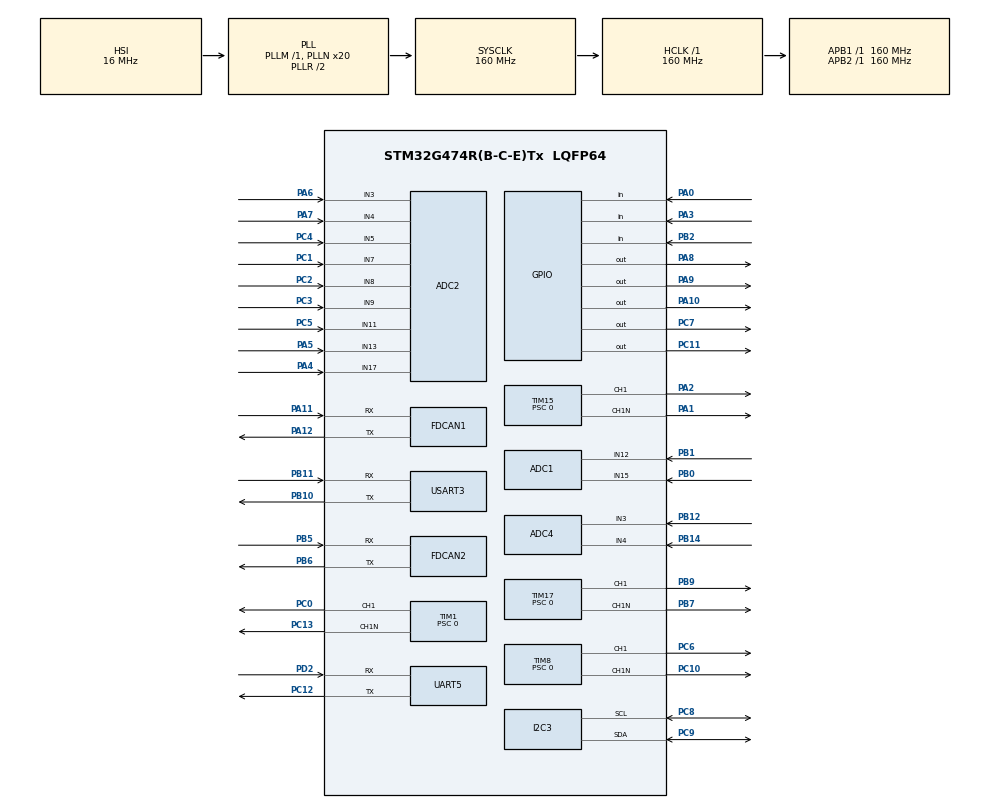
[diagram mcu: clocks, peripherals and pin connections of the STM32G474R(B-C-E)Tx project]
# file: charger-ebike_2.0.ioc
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ADC1.Channel-3\#ChannelRegularConversion=ADC_CHANNEL_15
ADC1.Channel-4\#ChannelRegularConversion=ADC_CHANNEL_12
ADC1.ContinuousConvMode=ENABLE
ADC1.DMAContinuousRequests=ENABLE
ADC1.NbrOfConversion=2
ADC1.NbrOfConversionFlag=1
ADC1.OffsetNumber-3\#ChannelRegularConversion=ADC_OFFSET_NONE
ADC1.OffsetNumber-4\#ChannelRegularConversion=ADC_OFFSET_NONE
ADC1.Rank-3\#ChannelRegularConversion=1
ADC1.Rank-4\#ChannelRegularConversion=2
ADC1.SamplingTime-3\#ChannelRegularConversion=ADC_SAMPLETIME_640CYCLES_5
ADC1.SamplingTime-4\#ChannelRegularConversion=ADC_SAMPLETIME_640CYCLES_5
ADC1.master=1
ADC2.Channel-0\#ChannelRegularConversion=ADC_CHANNEL_7
ADC2.Channel-1\#ChannelRegularConversion=ADC_CHANNEL_8
ADC2.Channel-2\#ChannelRegularConversion=ADC_CHANNEL_9
ADC2.Channel-3\#ChannelRegularConversion=ADC_CHANNEL_17
ADC2.Channel-4\#ChannelRegularConversion=ADC_CHANNEL_13
ADC2.Channel-5\#ChannelRegularConversion=ADC_CHANNEL_3
ADC2.Channel-6\#ChannelRegularConversion=ADC_CHANNEL_4
ADC2.Channel-7\#ChannelRegularConversion=ADC_CHANNEL_5
ADC2.Channel-8\#ChannelRegularConversion=ADC_CHANNEL_11
ADC2.ContinuousConvMode=ENABLE
ADC2.DMAContinuousRequests=ENABLE
ADC2.NbrOfConversion=9
ADC2.NbrOfConversionFlag=1
ADC2.OffsetNumber-0\#ChannelRegularConversion=ADC_OFFSET_NONE
ADC2.OffsetNumber-1\#ChannelRegularConversion=ADC_OFFSET_NONE
ADC2.OffsetNumber-2\#ChannelRegularConversion=ADC_OFFSET_NONE
ADC2.OffsetNumber-3\#ChannelRegularConversion=ADC_OFFSET_NONE
ADC2.OffsetNumber-4\#ChannelRegularConversion=ADC_OFFSET_NONE
ADC2.OffsetNumber-5\#ChannelRegularConversion=ADC_OFFSET_NONE
ADC2.OffsetNumber-6\#ChannelRegularConversion=ADC_OFFSET_NONE
ADC2.OffsetNumber-7\#ChannelRegularConversion=ADC_OFFSET_NONE
ADC2.OffsetNumber-8\#ChannelRegularConversion=ADC_OFFSET_NONE
ADC2.OversamplingMode=ENABLE
ADC2.Rank-0\#ChannelRegularConversion=1
ADC2.Rank-1\#ChannelRegularConversion=2
ADC2.Rank-2\#ChannelRegularConversion=3
ADC2.Rank-3\#ChannelRegularConversion=4
ADC2.Rank-4\#ChannelRegularConversion=5
ADC2.Rank-5\#ChannelRegularConversion=6
ADC2.Rank-6\#ChannelRegularConversion=7
ADC2.Rank-7\#ChannelRegularConversion=8
ADC2.Rank-8\#ChannelRegularConversion=9
ADC2.Ratio=ADC_OVERSAMPLING_RATIO_16
ADC2.RightBitShift=ADC_RIGHTBITSHIFT_4
ADC2.SamplingTime-0\#ChannelRegularConversion=ADC_SAMPLETIME_640CYCLES_5
ADC2.SamplingTime-1\#ChannelRegularConversion=ADC_SAMPLETIME_640CYCLES_5
ADC2.SamplingTime-2\#ChannelRegularConversion=ADC_SAMPLETIME_640CYCLES_5
ADC2.SamplingTime-3\#ChannelRegularConversion=ADC_SAMPLETIME_640CYCLES_5
ADC2.SamplingTime-4\#ChannelRegularConversion=ADC_SAMPLETIME_640CYCLES_5
ADC2.SamplingTime-5\#ChannelRegularConversion=ADC_SAMPLETIME_640CYCLES_5
ADC2.SamplingTime-6\#ChannelRegularConversion=ADC_SAMPLETIME_640CYCLES_5
ADC2.SamplingTime-7\#ChannelRegularConversion=ADC_SAMPLETIME_640CYCLES_5
ADC2.SamplingTime-8\#ChannelRegularConversion=ADC_SAMPLETIME_640CYCLES_5
ADC4.Channel-1\#ChannelRegularConversion=ADC_CHANNEL_3
ADC4.Channel-2\#ChannelRegularConversion=ADC_CHANNEL_4
ADC4.ContinuousConvMode=ENABLE
ADC4.DMAContinuousRequests=ENABLE
ADC4.NbrOfConversion=2
ADC4.NbrOfConversionFlag=1
ADC4.OffsetNumber-1\#ChannelRegularConversion=ADC_OFFSET_NONE
ADC4.OffsetNumber-2\#ChannelRegularConversion=ADC_OFFSET_NONE
ADC4.Rank-1\#ChannelRegularConversion=1
ADC4.Rank-2\#ChannelRegularConversion=2
ADC4.SamplingTime-1\#ChannelRegularConversion=ADC_SAMPLETIME_640CYCLES_5
ADC4.SamplingTime-2\#ChannelRegularConversion=ADC_SAMPLETIME_640CYCLES_5
Dma.ADC1.1.Direction=DMA_PERIPH_TO_MEMORY
Dma.ADC1.1.EventEnable=DISABLE
Dma.ADC1.1.Instance=DMA1_Channel2
Dma.ADC1.1.MemDataAlignment=DMA_MDATAALIGN_HALFWORD
Dma.ADC1.1.MemInc=DMA_MINC_ENABLE
Dma.ADC1.1.Mode=DMA_CIRCULAR
Dma.ADC1.1.PeriphDataAlignment=DMA_PDATAALIGN_HALFWORD
Dma.ADC1.1.PeriphInc=DMA_PINC_DISABLE
Dma.ADC1.1.Polarity=HAL_DMAMUX_REQ_GEN_RISING
Dma.ADC1.1.Priority=DMA_PRIORITY_LOW
Dma.ADC1.1.RequestNumber=1
Dma.ADC1.1.SignalID=NONE
Dma.ADC1.1.SyncEnable=DISABLE
Dma.ADC1.1.SyncPolarity=HAL_DMAMUX_SYNC_NO_EVENT
Dma.ADC1.1.SyncRequestNumber=1
Dma.ADC1.1.SyncSignalID=NONE
Dma.ADC2.0.Direction=DMA_PERIPH_TO_MEMORY
Dma.ADC2.0.EventEnable=DISABLE
Dma.ADC2.0.Instance=DMA1_Channel1
Dma.ADC2.0.MemDataAlignment=DMA_MDATAALIGN_HALFWORD
Dma.ADC2.0.MemInc=DMA_MINC_ENABLE
Dma.ADC2.0.Mode=DMA_CIRCULAR
Dma.ADC2.0.PeriphDataAlignment=DMA_PDATAALIGN_HALFWORD
Dma.ADC2.0.PeriphInc=DMA_PINC_DISABLE
Dma.ADC2.0.Polarity=HAL_DMAMUX_REQ_GEN_RISING
Dma.ADC2.0.Priority=DMA_PRIORITY_LOW
Dma.ADC2.0.RequestNumber=1
Dma.ADC2.0.SignalID=NONE
Dma.ADC2.0.SyncEnable=DISABLE
Dma.ADC2.0.SyncPolarity=HAL_DMAMUX_SYNC_NO_EVENT
Dma.ADC2.0.SyncRequestNumber=1
Dma.ADC2.0.SyncSignalID=NONE
Dma.ADC4.2.Direction=DMA_PERIPH_TO_MEMORY
Dma.ADC4.2.EventEnable=DISABLE
Dma.ADC4.2.Instance=DMA1_Channel3
Dma.ADC4.2.MemDataAlignment=DMA_MDATAALIGN_HALFWORD
Dma.ADC4.2.MemInc=DMA_MINC_ENABLE
Dma.ADC4.2.Mode=DMA_CIRCULAR
Dma.ADC4.2.PeriphDataAlignment=DMA_PDATAALIGN_HALFWORD
Dma.ADC4.2.PeriphInc=DMA_PINC_DISABLE
Dma.ADC4.2.Polarity=HAL_DMAMUX_REQ_GEN_RISING
Dma.ADC4.2.Priority=DMA_PRIORITY_LOW
Dma.ADC4.2.RequestNumber=1
Dma.ADC4.2.SignalID=NONE
Dma.ADC4.2.SyncEnable=DISABLE
Dma.ADC4.2.SyncPolarity=HAL_DMAMUX_SYNC_NO_EVENT
Dma.ADC4.2.SyncRequestNumber=1
Dma.ADC4.2.SyncSignalID=NONE
Dma.Request0=ADC2
Dma.Request1=ADC1
Dma.Request2=ADC4
FDCAN1.CalculateBaudRateNominal=500000
FDCAN1.CalculateTimeBitNominal=2000
FDCAN1.CalculateTimeQuantumNominal=200.0
FDCAN1.DataPrescaler=32
FDCAN1.DataTimeSeg1=4
FDCAN1.DataTimeSeg2=5
FDCAN1.NominalPrescaler=32
FDCAN1.NominalTimeSeg1=4
FDCAN1.NominalTimeSeg2=5
FDCAN2.CalculateBaudRateNominal=500000
FDCAN2.CalculateTimeBitNominal=2000
FDCAN2.CalculateTimeQuantumNominal=200.0
FDCAN2.DataPrescaler=32
FDCAN2.DataTimeSeg1=4
FDCAN2.DataTimeSeg2=5
FDCAN2.ExtFiltersNbr=1
FDCAN2.NominalPrescaler=32
FDCAN2.NominalTimeSeg1=4
FDCAN2.NominalTimeSeg2=5
FDCAN2.StdFiltersNbr=12
I2C3.Timing=0x30D29DE4
Mcu.Family=STM32G4
Mcu.Name=STM32G474R(B-C-E)Tx
Mcu.Package=LQFP64
NVIC.DMA1_Channel1_IRQn=true\:0\:0\:false\:false\:true\:false\:true\:true
NVIC.DMA1_Channel2_IRQn=true\:0\:0\:false\:false\:true\:false\:true\:true
NVIC.DMA1_Channel3_IRQn=true\:0\:0\:false\:false\:true\:false\:true\:true
NVIC.FDCAN1_IT0_IRQn=true\:0\:0\:false\:false\:true\:true\:true\:true
NVIC.FDCAN2_IT0_IRQn=true\:0\:0\:false\:false\:true\:true\:true\:true
NVIC.PriorityGroup=NVIC_PRIORITYGROUP_4
NVIC.TIM2_IRQn=true\:0\:0\:false\:false\:true\:true\:true\:true
NVIC.TIM3_IRQn=true\:0\:0\:false\:false\:true\:true\:true\:true
NVIC.USART3_IRQn=true\:0\:0\:false\:false\:true\:true\:true\:true
PA0.Signal=GPIO_Input
PA1.GPIO_PuPd=GPIO_NOPULL
PA1.GPIO_Speed=GPIO_SPEED_FREQ_LOW
PA1.Mode=PWM Generation1 CH1 CH1N
PA1.Signal=TIM15_CH1N
PA10.Signal=GPIO_Output
PA11.Mode=FDCAN_Activate
PA11.Signal=FDCAN1_RX
PA12.Mode=FDCAN_Activate
PA12.Signal=FDCAN1_TX
PA13.Mode=Serial_Wire
PA13.Signal=SYS_JTMS-SWDIO
PA14.Mode=Serial_Wire
PA14.Signal=SYS_JTCK-SWCLK
PA2.GPIO_PuPd=GPIO_NOPULL
PA2.GPIO_Speed=GPIO_SPEED_FREQ_LOW
PA2.Signal=S_TIM15_CH1
PA3.GPIO_PuPd=GPIO_PULLDOWN
PA3.Signal=GPIO_Input
PA4.Mode=IN17-Single-Ended
PA4.Signal=ADC2_IN17
PA5.Mode=IN13-Single-Ended
PA5.Signal=ADC2_IN13
PA6.Mode=IN3-Single-Ended
PA6.Signal=ADC2_IN3
PA7.Mode=IN4-Single-Ended
PA7.Signal=ADC2_IN4
PA8.Signal=GPIO_Output
PA9.Signal=GPIO_Output
PB0.Mode=IN15-Single-Ended
PB0.Signal=ADC1_IN15
PB1.Mode=IN12-Single-Ended
PB1.Signal=ADC1_IN12
PB10.Mode=Asynchronous
PB10.Signal=USART3_TX
PB11.Mode=Asynchronous
PB11.Signal=USART3_RX
PB12.Mode=IN3-Single-Ended
PB12.Signal=ADC4_IN3
PB14.Mode=IN4-Single-Ended
PB14.Signal=ADC4_IN4
PB2.Signal=GPIO_Input
PB5.Mode=FDCAN_Activate
PB5.Signal=FDCAN2_RX
PB6.Mode=FDCAN_Activate
PB6.Signal=FDCAN2_TX
PB7.GPIO_Speed=GPIO_SPEED_FREQ_LOW
PB7.Mode=PWM Generation1 CH1 CH1N
PB7.Signal=TIM17_CH1N
PB9.GPIO_Speed=GPIO_SPEED_FREQ_LOW
PB9.Signal=S_TIM17_CH1
PC0.GPIO_Speed=GPIO_SPEED_FREQ_LOW
PC0.Signal=S_TIM1_CH1
PC1.Mode=IN7-Single-Ended
PC1.Signal=ADC2_IN7
PC10.GPIO_Speed=GPIO_SPEED_FREQ_LOW
PC10.Mode=PWM Generation1 CH1 CH1N
PC10.Signal=TIM8_CH1N
PC11.Signal=GPIO_Output
PC12.Mode=Asynchronous
PC12.Signal=UART5_TX
PC13.Mode=PWM Generation1 CH1 CH1N
PC13.Signal=TIM1_CH1N
PC2.Mode=IN8-Single-Ended
PC2.Signal=ADC2_IN8
PC3.Mode=IN9-Single-Ended
PC3.Signal=ADC2_IN9
PC4.Mode=IN5-Single-Ended
PC4.Signal=ADC2_IN5
PC5.Mode=IN11-Single-Ended
PC5.Signal=ADC2_IN11
PC6.GPIO_Speed=GPIO_SPEED_FREQ_LOW
PC6.Signal=S_TIM8_CH1
PC7.Signal=GPIO_Output
PC8.Mode=I2C
PC8.Signal=I2C3_SCL
PC9.Mode=I2C
PC9.Signal=I2C3_SDA
PD2.Mode=Asynchronous
PD2.Signal=UART5_RX
ProjectManager.HeapSize=0x200
ProjectManager.StackSize=0x400
ProjectManager.TargetToolchain=MDK-ARM V5.32
RCC.ADC12Freq_Value=160000000
RCC.ADC345Freq_Value=160000000
RCC.AHBFreq_Value=160000000
RCC.APB1Freq_Value=160000000
RCC.APB1TimFreq_Value=160000000
RCC.APB2Freq_Value=160000000
RCC.APB2TimFreq_Value=160000000
RCC.CortexFreq_Value=160000000
RCC.EXTERNAL_CLOCK_VALUE=12288000
RCC.HCLKFreq_Value=160000000
RCC.HSE_VALUE=8000000
RCC.HSI48_VALUE=48000000
RCC.HSI_VALUE=16000000
RCC.LSE_VALUE=32768
RCC.PLLN=20
RCC.SYSCLKFreq_VALUE=160000000
RCC.SYSCLKSource=RCC_SYSCLKSOURCE_PLLCLK
RCC.USBFreq_Value=160000000
RCC.VCOOutputFreq_Value=320000000
SH.S_TIM15_CH1.0=TIM15_CH1,PWM Generation1 CH1 CH1N
SH.S_TIM17_CH1.0=TIM17_CH1,PWM Generation1 CH1 CH1N
SH.S_TIM1_CH1.0=TIM1_CH1,PWM Generation1 CH1 CH1N
SH.S_TIM8_CH1.0=TIM8_CH1,PWM Generation1 CH1 CH1N
TIM1.AutoReloadPreload=TIM_AUTORELOAD_PRELOAD_DISABLE
TIM1.Channel-PWM\ Generation1\ CH1\ CH1N=TIM_CHANNEL_1
TIM1.PeriodNoDither=1599
TIM1.Prescaler=0
TIM1.PulseNoDither_1=0
TIM1.RepetitionCounter=0
TIM15.AutoReloadPreload=TIM_AUTORELOAD_PRELOAD_DISABLE
TIM15.Channel-PWM\ Generation1\ CH1\ CH1N=TIM_CHANNEL_1
TIM15.PeriodNoDither=1599
TIM15.Prescaler=0
TIM15.PulseNoDither_1=0
TIM15.RepetitionCounter=0
TIM17.AutoReloadPreload=TIM_AUTORELOAD_PRELOAD_DISABLE
TIM17.Channel=TIM_CHANNEL_1
TIM17.PeriodNoDither=1599
TIM17.Prescaler=0
TIM17.PulseNoDither_1=0
TIM2.PeriodNoDither=999
TIM2.Prescaler=1599
TIM3.PeriodNoDither=1599
TIM8.AutoReloadPreload=TIM_AUTORELOAD_PRELOAD_DISABLE
TIM8.Channel-PWM\ Generation1\ CH1\ CH1N=TIM_CHANNEL_1
TIM8.PeriodNoDither=1599
TIM8.Prescaler=0
TIM8.PulseNoDither_1=0
USART3.VirtualMode-Asynchronous=VM_ASYNC
VP_SYS_VS_DBSignals.Mode=DisableDeadBatterySignals
VP_TIM15_VS_ClockSourceINT.Mode=Internal
VP_TIM17_VS_ClockSourceINT.Mode=Enable_Timer
VP_TIM1_VS_ClockSourceINT.Mode=Internal
VP_TIM2_VS_ClockSourceINT.Mode=Internal
VP_TIM3_VS_ClockSourceINT.Mode=Internal
VP_TIM8_VS_ClockSourceINT.Mode=Internal
board=custom

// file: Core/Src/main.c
/* USER CODE BEGIN Header */
/**
  ******************************************************************************
  * @file           : main.c
  * @brief          : Main program body
  ******************************************************************************
  * @attention
  *
  * Copyright (c) 2025 STMicroelectronics.
  * All rights reserved.
  *
  * This software is licensed under terms that can be found in the LICENSE file
  * in the root directory of this software component.
  * If no LICENSE file comes with this software, it is provided AS-IS.
  *
  ******************************************************************************
  */
/* USER CODE END Header */
#include "main.h"

/* USER CODE BEGIN Includes */
#include "charger.h"
#include "process_data.h"
#include "fdcan.h"
#include <string.h>
#include <stdio.h>
/* USER CODE END Includes */

/* USER CODE BEGIN PM */
// #define ROUND(value) ((value) >= 0 ? (int)((value) + 0.5f) : (int)((value) - 0.5f))
/* USER CODE END PM */

ADC_HandleTypeDef hadc1;
ADC_HandleTypeDef hadc2;
ADC_HandleTypeDef hadc4;
DMA_HandleTypeDef hdma_adc1;
DMA_HandleTypeDef hdma_adc2;
DMA_HandleTypeDef hdma_adc4;

FDCAN_HandleTypeDef hfdcan1;
FDCAN_HandleTypeDef hfdcan2;

I2C_HandleTypeDef hi2c3;

TIM_HandleTypeDef htim1;
TIM_HandleTypeDef htim2;
TIM_HandleTypeDef htim3;
TIM_HandleTypeDef htim8;
TIM_HandleTypeDef htim15;
TIM_HandleTypeDef htim17;

UART_HandleTypeDef huart5;
UART_HandleTypeDef huart3;

/* USER CODE BEGIN PV */

uint8_t enable_charger_controller = 0;
uint8_t flag_BMS0_read = 1;
uint8_t flag_BMS1_read = 1;
volatile uint8_t flag_BMS0_alive = 0, flag_BMS1_alive = 0;
uint32_t pre_time_BMS0, cur_time_BMS0;
uint32_t pre_time_BMS1, cur_time_BMS1;

char buffer_stage[40] = {0};
char buffer_case[40] = {0};
uint16_t u16_ADC1_Val[2] = {0};
uint16_t u16_ADC2_Val[9] = {0};
uint16_t u16_ADC4_Val[2] = {0};
uint16_t u16_ADC1_Val_average[2] = {0};
uint16_t u16_ADC2_Val_average[9] = {0};
uint16_t u16_ADC4_Val_average[2] = {0};

/* USER CODE END PV */

void SystemClock_Config(void);
static void MX_GPIO_Init(void);
static void MX_DMA_Init(void);
static void MX_ADC1_Init(void);
static void MX_ADC2_Init(void);
static void MX_ADC4_Init(void);
static void MX_FDCAN1_Init(void);
static void MX_FDCAN2_Init(void);
static void MX_I2C3_Init(void);
static void MX_TIM1_Init(void);
static void MX_TIM2_Init(void);
static void MX_TIM8_Init(void);
static void MX_TIM15_Init(void);
static void MX_TIM17_Init(void);
static void MX_UART5_Init(void);
static void MX_USART3_UART_Init(void);
static void MX_TIM3_Init(void);

/* USER CODE BEGIN 0 */
void HAL_UART_RxCpltCallback(UART_HandleTypeDef *huart)
{
	if(huart->Instance == USART3)
  {
	  uint8_t RxLength = 0;
		HAL_UART_Receive_IT(&huart3, (uint8_t*)RxDataChar, 1);

//		if (RxDataChar[0] == HeaderString[RxDataIndex] || RxDataIndex > 5) {		// Check data has header 'EBIKE-'
		if (RxDataChar[0] == HeaderString[RxDataIndex] || RxDataIndex > 2) {			// Check data has header 'EB-'
			RxDataString[RxDataIndex] = RxDataChar[0];
			RxDataIndex++;
			if(RxDataChar[0] == ';' || RxDataIndex == 5) { // current receive each line
				receive_cmd = 1;
				RxDataIndex = 0;
			}
		} else {
			memset(RxDataString, 0, sizeof(RxDataString));
			RxDataString[0] = RxDataChar[0];
			RxDataIndex = 1;
		}

  }
}
/* USER CODE END 0 */

int main(void)
{

  /* USER CODE BEGIN 1 */
  SCB->VTOR = (uint32_t)0x08040000;
	__enable_irq();
	char buffer[] = "hello\r\n";
  /* USER CODE END 1 */

  /* MCU Configuration--------------------------------------------------------*/

  /* Reset of all peripherals, Initializes the Flash interface and the Systick. */
  HAL_Init();

  /* Configure the system clock */
  SystemClock_Config();

  /* Initialize all configured peripherals */
  MX_GPIO_Init();
  MX_DMA_Init();
  MX_ADC1_Init();
  MX_ADC2_Init();
  MX_ADC4_Init();
  MX_FDCAN1_Init();
  MX_FDCAN2_Init();
  MX_I2C3_Init();
  MX_TIM1_Init();
  MX_TIM2_Init();
  MX_TIM8_Init();
  MX_TIM15_Init();
  MX_TIM17_Init();
  MX_UART5_Init();
  MX_USART3_UART_Init();
  MX_TIM3_Init();
  /* USER CODE BEGIN 2 */
  // init Independent Watchdog Timeout
//	while (!enable_charger_controller);
  //HAL_IWDG_Init(&hiwdg);

	FDCAN_Config();
	HAL_UART_Receive_IT(&huart3, (uint8_t*)RxDataChar, 1);

	// Calibrate ADC before call HAL_ADC_Start/HAL_ADC_Start_DMA
	HAL_ADCEx_Calibration_Start(&hadc1, ADC_SINGLE_ENDED);
	HAL_ADCEx_Calibration_Start(&hadc2, ADC_SINGLE_ENDED);
	HAL_ADCEx_Calibration_Start(&hadc4, ADC_SINGLE_ENDED);
	HAL_Delay(100);
	// Trigger read ADC DMA in contious mode
	HAL_ADC_Start_DMA(&hadc1, (uint32_t*)u16_ADC1_Val, 2);
	HAL_ADC_Start_DMA(&hadc2, (uint32_t*)u16_ADC2_Val, 9);
	HAL_ADC_Start_DMA(&hadc4, (uint32_t*)u16_ADC4_Val, 2);
	HAL_Delay(100);

	// BUCK mode
	PID_Init(&pid_caseD1, 200, 20, 0.05); // Setting Kp, Ki, Kd. Need to be change
	PID_Init(&pid_caseD2, 250, 20, 0.05); // Setting Kp, Ki, Kd. Need to be change
	PID_Init(&pid_caseD3, 80, 2, 0.05); // Setting Kp, Ki, Kd. Need to be change
	PID_Init(&pid_caseD4, 80, 20, 0.05); // Setting Kp, Ki, Kd. Need to be change
	PID_Init(&pid_caseD4_Phase1_Cur, 80, 5, 0.05); // Setting Kp, Ki, Kd. Need to be change
	PID_Init(&pid_caseD4_Phase2_Cur, 80, 5, 0.05); // Setting Kp, Ki, Kd. Need to be change
	PID_Init(&pid_caseD5, 80, 21, 0.05); // Setting Kp, Ki, Kd. Need to be change
	PID_Init(&pid_caseD5_Phase1_Cur, 80, 1.2, 0.05); // Setting Kp, Ki, Kd. Need to be change
	PID_Init(&pid_caseD5_Phase2_Cur, 80, 1.2, 0.05); // Setting Kp, Ki, Kd. Need to be change
	PID_Init(&pid_caseD6, 80, 20, 0.05); // TSetting Kp, Ki, Kd. Need to be change

	// BOOST mode
	PID_Init(&pid_caseU11, 50, 1.1, 0.05); // Setting Kp, Ki, Kd. Need to be change
	PID_Init(&pid_caseU12, 50, 3.5, 0.05); // Setting Kp, Ki, Kd. Need to be change
	PID_Init(&pid_caseU12, 50, 5, 0.05); // Setting Kp, Ki, Kd. Need to be change
	PID_Init(&pid_caseU14, 60, 5, 0.05); // Setting Kp, Ki, Kd. Need to be change
	PID_Init(&pid_caseU14_Phase1_Cur, 8, 1.2, 0.05); // Setting Kp, Ki, Kd. Need to be change
	PID_Init(&pid_caseU14_Phase2_Cur, 8, 1.2, 0.05); // Setting Kp, Ki, Kd. Need to be change
	PID_Init(&pid_caseU15, 60, 0.01, 0.05); // Setting Kp, Ki, Kd. Need to be change
	PID_Init(&pid_caseU15_Phase1_Cur, 8, 1.2, 0.05); // Setting Kp, Ki, Kd. Need to be change
	PID_Init(&pid_caseU15_Phase2_Cur, 8, 1.2, 0.05); // Setting Kp, Ki, Kd. Need to be change
	PID_Init(&pid_caseU16, 70, 0.01, 0.05); // TSetting Kp, Ki, Kd. Need to be change

	// enable Timer 2 Interupt
  HAL_TIM_Base_Start_IT(&htim2);
	HAL_TIM_Base_Start_IT(&htim3);

	// Send version
	HAL_UART_Transmit(&huart3, (uint8_t *)"v1.1.1\r\n", strlen("v1.0.1\r\n"), HAL_MAX_DELAY);
#ifdef DEBUG
	memset(buffer_stage, 0, sizeof(buffer_stage));
	snprintf(buffer_stage, 40, "current_stage = %s\r\n", List_Stage[current_stage]);
	HAL_UART_Transmit(&huart3, (uint8_t *)buffer_stage, strlen(buffer_stage), HAL_MAX_DELAY);
#endif

	pre_time_BMS0 = HAL_GetTick();
	pre_time_BMS1 = HAL_GetTick();
  /* USER CODE END 2 */

  /* Infinite loop */
  while (1)
  {

    /* USER CODE BEGIN 3 */
		// DEBUG stage and case.
#ifdef DEBUG
		if (previous_stage != current_stage) {
			memset(buffer_stage, 0, sizeof(buffer_stage));
			snprintf(buffer_stage, 40, "current_stage = %s\r\n", List_Stage[current_stage]);
			HAL_UART_Transmit(&huart3, (uint8_t *)buffer_stage, strlen(buffer_stage), HAL_MAX_DELAY);
			previous_stage = current_stage;
		}
#endif
		if (previous_case != current_case) {
			flag1_D6 = flag2_D6 = 0;
      flag1_U16 = flag2_U16 = 0;
			counter_Chg_Current_Adc_over_target = 0;
			// Init again PID everytime CASE is changed
			// BUCK mode
			PID_Init(&pid_caseD1, 200, 20, 0.05); // Setting Kp, Ki, Kd. Need to be change
			PID_Init(&pid_caseD2, 250, 20, 0.05); // Setting Kp, Ki, Kd. Need to be change
			PID_Init(&pid_caseD3, 80, 2, 0.05); // Setting Kp, Ki, Kd. Need to be change
			PID_Init(&pid_caseD4, 80, 20, 0.05); // Setting Kp, Ki, Kd. Need to be change
			PID_Init(&pid_caseD4_Phase1_Cur, 80, 5, 0.05); // Setting Kp, Ki, Kd. Need to be change
			PID_Init(&pid_caseD4_Phase2_Cur, 80, 5, 0.05); // Setting Kp, Ki, Kd. Need to be change
			PID_Init(&pid_caseD5, 80, 21, 0.05); // Setting Kp, Ki, Kd. Need to be change
			PID_Init(&pid_caseD5_Phase1_Cur, 80, 1.2, 0.05); // Setting Kp, Ki, Kd. Need to be change
			PID_Init(&pid_caseD5_Phase2_Cur, 80, 1.2, 0.05); // Setting Kp, Ki, Kd. Need to be change
			PID_Init(&pid_caseD6, 80, 20, 0.05); // TSetting Kp, Ki, Kd. Need to be change
			// BOOST mode
			PID_Init(&pid_caseU11, 50, 1.1, 0.05); // Setting Kp, Ki, Kd. Need to be change
			PID_Init(&pid_caseU12, 50, 3.5, 0.05); // Setting Kp, Ki, Kd. Need to be change
			PID_Init(&pid_caseU12, 50, 5, 0.05); // Setting Kp, Ki, Kd. Need to be change
			PID_Init(&pid_caseU14, 60, 5, 0.05); // Setting Kp, Ki, Kd. Need to be change
			PID_Init(&pid_caseU14_Phase1_Cur, 8, 1.2, 0.05); // Setting Kp, Ki, Kd. Need to be change
			PID_Init(&pid_caseU14_Phase2_Cur, 8, 1.2, 0.05); // Setting Kp, Ki, Kd. Need to be change
			PID_Init(&pid_caseU15, 60, 0.01, 0.05); // Setting Kp, Ki, Kd. Need to be change
			PID_Init(&pid_caseU15_Phase1_Cur, 8, 1.2, 0.05); // Setting Kp, Ki, Kd. Need to be change
			PID_Init(&pid_caseU15_Phase2_Cur, 8, 1.2, 0.05); // Setting Kp, Ki, Kd. Need to be change
			PID_Init(&pid_caseU16, 70, 0.01, 0.05); // TSetting Kp, Ki, Kd. Need to be change

			if (hardware_protection_flag == 0 && software_protection_flag == 0) {
				if (current_case == caseD1 || current_case == caseD3 || current_case == caseD6) {
					// Start BUCK1, Stop BUCK2 & BOOST1 & BOOST2
					HAL_TIM_PWM_Start(&htim15,TIM_CHANNEL_1);						// BUCK1
					HAL_TIMEx_PWMN_Start(&htim15,TIM_CHANNEL_1);
					HAL_TIM_PWM_Stop(&htim17,TIM_CHANNEL_1);						// BUCK2
					HAL_TIMEx_PWMN_Stop(&htim17,TIM_CHANNEL_1);

					HAL_TIM_PWM_Stop(&htim1,TIM_CHANNEL_1);							// BOOST1
					HAL_TIMEx_PWMN_Stop(&htim1,TIM_CHANNEL_1);
					HAL_TIM_PWM_Stop(&htim8,TIM_CHANNEL_1);							// BOOST2
					HAL_TIMEx_PWMN_Stop(&htim8,TIM_CHANNEL_1);

					duty_cycle_BUCK1 = 10;
					duty_cycle_BUCK2 = 0;
					duty_cycle_BOOST1 = 0;
					duty_cycle_BOOST2 = 0;
				} else if (current_case == caseD2) {
					// Start BUCK1, Stop BUCK2 & BOOST1 & BOOST2
					HAL_TIM_PWM_Start(&htim15,TIM_CHANNEL_1);						// BUCK1
					HAL_TIMEx_PWMN_Start(&htim15,TIM_CHANNEL_1);
					HAL_TIM_PWM_Stop(&htim17,TIM_CHANNEL_1);						// BUCK2
					HAL_TIMEx_PWMN_Stop(&htim17,TIM_CHANNEL_1);

					HAL_TIM_PWM_Stop(&htim1,TIM_CHANNEL_1);							// BOOST1
					HAL_TIMEx_PWMN_Stop(&htim1,TIM_CHANNEL_1);
					HAL_TIM_PWM_Stop(&htim8,TIM_CHANNEL_1);							// BOOST2
					HAL_TIMEx_PWMN_Stop(&htim8,TIM_CHANNEL_1);

					duty_cycle_BUCK1 = 0;
					duty_cycle_BUCK2 = 0;
					duty_cycle_BOOST1 = 0;
					duty_cycle_BOOST2 = 0;
				} else if (current_case == caseD4 || current_case == caseD5) {
					// Start BUCK1 & BUCK2, Stop BOOST1 & BOOST2
//					HAL_TIM_PWM_Start(&htim15,TIM_CHANNEL_1);						// BUCK1
//					HAL_TIMEx_PWMN_Start(&htim15,TIM_CHANNEL_1);
//					HAL_TIM_PWM_Start(&htim17,TIM_CHANNEL_1);						// BUCK2
//					HAL_TIMEx_PWMN_Start(&htim17,TIM_CHANNEL_1);

					HAL_TIM_PWM_Stop(&htim1,TIM_CHANNEL_1);							// BOOST1
					HAL_TIMEx_PWMN_Stop(&htim1,TIM_CHANNEL_1);
					HAL_TIM_PWM_Stop(&htim8,TIM_CHANNEL_1);							// BOOST2
					HAL_TIMEx_PWMN_Stop(&htim8,TIM_CHANNEL_1);

					duty_cycle_BUCK1 = 10;
					duty_cycle_BUCK2 = 10;
					duty_cycle_BOOST1 = 0;
					duty_cycle_BOOST2 = 0;
				} else if (current_case == caseU11 || current_case == caseU12 || current_case == caseU13 || current_case == caseU16) {
					// Start BOOST1, Stop BUCK1 & BUCK2 & BOOST2
					HAL_TIM_PWM_Stop(&htim15,TIM_CHANNEL_1);						// BUCK1
					HAL_TIMEx_PWMN_Stop(&htim15,TIM_CHANNEL_1);
					HAL_TIM_PWM_Stop(&htim17,TIM_CHANNEL_1);						// BUCK2
					HAL_TIMEx_PWMN_Stop(&htim17,TIM_CHANNEL_1);

					HAL_TIM_PWM_Start(&htim1,TIM_CHANNEL_1);						// BOOST1
					HAL_TIMEx_PWMN_Start(&htim1,TIM_CHANNEL_1);
					HAL_TIM_PWM_Stop(&htim8,TIM_CHANNEL_1);							// BOOST2
					HAL_TIMEx_PWMN_Stop(&htim8,TIM_CHANNEL_1);

					duty_cycle_BUCK1 = 0;
					duty_cycle_BUCK2 = 0;
					duty_cycle_BOOST1 = 0;
					duty_cycle_BOOST2 = 0;
				} else if (current_case == caseU14 || current_case == caseU15) {
					// Start BOOST1 & BOOST2, Stop BUCK1 & BUCK2
					HAL_TIM_PWM_Stop(&htim15,TIM_CHANNEL_1);						// BUCK1
					HAL_TIMEx_PWMN_Stop(&htim15,TIM_CHANNEL_1);
					HAL_TIM_PWM_Stop(&htim17,TIM_CHANNEL_1);						// BUCK2
					HAL_TIMEx_PWMN_Stop(&htim17,TIM_CHANNEL_1);

//					HAL_TIM_PWM_Start(&htim1,TIM_CHANNEL_1);						// BOOST1
//					HAL_TIMEx_PWMN_Start(&htim1,TIM_CHANNEL_1);
//					HAL_TIM_PWM_Start(&htim8,TIM_CHANNEL_1);						// BOOST2
//					HAL_TIMEx_PWMN_Start(&htim8,TIM_CHANNEL_1);

					duty_cycle_BUCK1 = 0;
					duty_cycle_BUCK2 = 0;
					duty_cycle_BOOST1 = 0;
					duty_cycle_BOOST2 = 0;
				} else {
					// Stop BUCK1 & BUCK2 & BOOST1 & BOOST2
					HAL_TIM_PWM_Stop(&htim15,TIM_CHANNEL_1);						// BUCK1
					HAL_TIMEx_PWMN_Stop(&htim15,TIM_CHANNEL_1);
					HAL_TIM_PWM_Stop(&htim17,TIM_CHANNEL_1);						// BUCK2
					HAL_TIMEx_PWMN_Stop(&htim17,TIM_CHANNEL_1);

					HAL_TIM_PWM_Stop(&htim1,TIM_CHANNEL_1);							// BOOST1
					HAL_TIMEx_PWMN_Stop(&htim1,TIM_CHANNEL_1);
					HAL_TIM_PWM_Stop(&htim8,TIM_CHANNEL_1);							// BOOST2
					HAL_TIMEx_PWMN_Stop(&htim8,TIM_CHANNEL_1);
					duty_cycle_BUCK1 = 0;
					duty_cycle_BUCK2 = 0;
					duty_cycle_BOOST1 = 0;
					duty_cycle_BOOST2 = 0;
				}

  			SetDutyCircle_BUCK1(duty_cycle_BUCK1, 1);
  			SetDutyCircle_BUCK2(duty_cycle_BUCK2, 1);
  			SetDutyCircle_BOOST1(duty_cycle_BOOST1, 1);
  			SetDutyCircle_BOOST2(duty_cycle_BOOST2, 1);
#ifdef DEBUG
  			memset(buffer_case, 0, sizeof(buffer_case));
  			snprintf(buffer_case, 40, "current_case = %s\r\n", List_Case[current_case]);
  			HAL_UART_Transmit(&huart3, (uint8_t *)buffer_case, strlen(buffer_case), HAL_MAX_DELAY);
#endif
  			previous_case = current_case;
				if (current_case != caseD5 && current_case != caseU15) HAL_Delay(1000);
			}
		}
		flow_chart_ebike_stage();
		query_data(); // Query all data eg ADC, I2C, voltage, current
		received_command();	// handle data send in UART/CAN

		if (counter_CAN_BMS >= 100) {		// every 1s, read data from BMS0 and BMS1
//			send_data();				// Send data to monitoring tools
			if (flag_BMS0_read == 1) {
				cur_time_BMS0 = HAL_GetTick();
				if ((cur_time_BMS0 - pre_time_BMS0) > FDCAN_TX_DELAY_MS) {
					flag_BMS0_read = CAN_BMS0_read_data();
					pre_time_BMS0 = cur_time_BMS0;
				}
			}

			if (flag_BMS1_read == 1) {
				cur_time_BMS1 = HAL_GetTick();
				if ((cur_time_BMS1 - pre_time_BMS1) > FDCAN_TX_DELAY_MS) {
					flag_BMS1_read = CAN_BMS1_read_data();
					pre_time_BMS1 = cur_time_BMS1;
				}
			}
			if (flag_BMS0_read == 0 && flag_BMS1_read == 0 ) {
				// when read BMS0 and BMS1 completely, check BMS alive or not
				AuxBattery0_Info[26] = flag_BMS0_alive;
				AuxBattery1_Info[26] = flag_BMS1_alive;
				counter_CAN_BMS = 0;
				flag_BMS0_read = 1;
				flag_BMS1_read = 1;
				flag_BMS0_alive = 0;
				flag_BMS1_alive = 0;
			}
		}

  }
  /* USER CODE END 3 */
}

void SystemClock_Config(void)
{
  RCC_OscInitTypeDef RCC_OscInitStruct = {0};
  RCC_ClkInitTypeDef RCC_ClkInitStruct = {0};

  /** Configure the main internal regulator output voltage
  */
  HAL_PWREx_ControlVoltageScaling(PWR_REGULATOR_VOLTAGE_SCALE1_BOOST);

  /** Initializes the RCC Oscillators according to the specified parameters
  * in the RCC_OscInitTypeDef structure.
  */
  RCC_OscInitStruct.OscillatorType = RCC_OSCILLATORTYPE_HSI;
  RCC_OscInitStruct.HSIState = RCC_HSI_ON;
  RCC_OscInitStruct.HSICalibrationValue = RCC_HSICALIBRATION_DEFAULT;
  RCC_OscInitStruct.PLL.PLLState = RCC_PLL_ON;
  RCC_OscInitStruct.PLL.PLLSource = RCC_PLLSOURCE_HSI;
  RCC_OscInitStruct.PLL.PLLM = RCC_PLLM_DIV1;
  RCC_OscInitStruct.PLL.PLLN = 20;
  RCC_OscInitStruct.PLL.PLLP = RCC_PLLP_DIV2;
  RCC_OscInitStruct.PLL.PLLQ = RCC_PLLQ_DIV2;
  RCC_OscInitStruct.PLL.PLLR = RCC_PLLR_DIV2;
  if (HAL_RCC_OscConfig(&RCC_OscInitStruct) != HAL_OK)
  {
    Error_Handler();
  }

  /** Initializes the CPU, AHB and APB buses clocks
  */
  RCC_ClkInitStruct.ClockType = RCC_CLOCKTYPE_HCLK|RCC_CLOCKTYPE_SYSCLK
                              |RCC_CLOCKTYPE_PCLK1|RCC_CLOCKTYPE_PCLK2;
  RCC_ClkInitStruct.SYSCLKSource = RCC_SYSCLKSOURCE_PLLCLK;
  RCC_ClkInitStruct.AHBCLKDivider = RCC_SYSCLK_DIV1;
  RCC_ClkInitStruct.APB1CLKDivider = RCC_HCLK_DIV1;
  RCC_ClkInitStruct.APB2CLKDivider = RCC_HCLK_DIV1;

  if (HAL_RCC_ClockConfig(&RCC_ClkInitStruct, FLASH_LATENCY_4) != HAL_OK)
  {
    Error_Handler();
  }
}

static void MX_ADC1_Init(void)
{

  ADC_MultiModeTypeDef multimode = {0};
  ADC_ChannelConfTypeDef sConfig = {0};

  /** Common config
  */
  hadc1.Instance = ADC1;
  hadc1.Init.ClockPrescaler = ADC_CLOCK_SYNC_PCLK_DIV4;
  hadc1.Init.Resolution = ADC_RESOLUTION_12B;
  hadc1.Init.DataAlign = ADC_DATAALIGN_RIGHT;
  hadc1.Init.GainCompensation = 0;
  hadc1.Init.ScanConvMode = ADC_SCAN_ENABLE;
  hadc1.Init.EOCSelection = ADC_EOC_SINGLE_CONV;
  hadc1.Init.LowPowerAutoWait = DISABLE;
  hadc1.Init.ContinuousConvMode = ENABLE;
  hadc1.Init.NbrOfConversion = 2;
  hadc1.Init.DiscontinuousConvMode = DISABLE;
  hadc1.Init.ExternalTrigConv = ADC_SOFTWARE_START;
  hadc1.Init.ExternalTrigConvEdge = ADC_EXTERNALTRIGCONVEDGE_NONE;
  hadc1.Init.DMAContinuousRequests = ENABLE;
  hadc1.Init.Overrun = ADC_OVR_DATA_PRESERVED;
  hadc1.Init.OversamplingMode = DISABLE;
  if (HAL_ADC_Init(&hadc1) != HAL_OK)
  {
    Error_Handler();
  }

  /** Configure the ADC multi-mode
  */
  multimode.Mode = ADC_MODE_INDEPENDENT;
  if (HAL_ADCEx_MultiModeConfigChannel(&hadc1, &multimode) != HAL_OK)
  {
    Error_Handler();
  }

  /** Configure Regular Channel
  */
  sConfig.Channel = ADC_CHANNEL_15;
  sConfig.Rank = ADC_REGULAR_RANK_1;
  sConfig.SamplingTime = ADC_SAMPLETIME_640CYCLES_5;
  sConfig.SingleDiff = ADC_SINGLE_ENDED;
  sConfig.OffsetNumber = ADC_OFFSET_NONE;
  sConfig.Offset = 0;
  if (HAL_ADC_ConfigChannel(&hadc1, &sConfig) != HAL_OK)
  {
    Error_Handler();
  }

  /** Configure Regular Channel
  */
  sConfig.Channel = ADC_CHANNEL_12;
  sConfig.Rank = ADC_REGULAR_RANK_2;
  if (HAL_ADC_ConfigChannel(&hadc1, &sConfig) != HAL_OK)
  {
    Error_Handler();
  }

}

static void MX_ADC2_Init(void)
{

  ADC_ChannelConfTypeDef sConfig = {0};

  /** Common config
  */
  hadc2.Instance = ADC2;
  hadc2.Init.ClockPrescaler = ADC_CLOCK_SYNC_PCLK_DIV4;
  hadc2.Init.Resolution = ADC_RESOLUTION_12B;
  hadc2.Init.DataAlign = ADC_DATAALIGN_RIGHT;
  hadc2.Init.GainCompensation = 0;
  hadc2.Init.ScanConvMode = ADC_SCAN_ENABLE;
  hadc2.Init.EOCSelection = ADC_EOC_SINGLE_CONV;
  hadc2.Init.LowPowerAutoWait = DISABLE;
  hadc2.Init.ContinuousConvMode = ENABLE;
  hadc2.Init.NbrOfConversion = 9;
  hadc2.Init.DiscontinuousConvMode = DISABLE;
  hadc2.Init.ExternalTrigConv = ADC_SOFTWARE_START;
  hadc2.Init.ExternalTrigConvEdge = ADC_EXTERNALTRIGCONVEDGE_NONE;
  hadc2.Init.DMAContinuousRequests = ENABLE;
  hadc2.Init.Overrun = ADC_OVR_DATA_PRESERVED;
  hadc2.Init.OversamplingMode = ENABLE;
  hadc2.Init.Oversampling.Ratio = ADC_OVERSAMPLING_RATIO_16;
  hadc2.Init.Oversampling.RightBitShift = ADC_RIGHTBITSHIFT_4;
  hadc2.Init.Oversampling.TriggeredMode = ADC_TRIGGEREDMODE_SINGLE_TRIGGER;
  hadc2.Init.Oversampling.OversamplingStopReset = ADC_REGOVERSAMPLING_CONTINUED_MODE;
  if (HAL_ADC_Init(&hadc2) != HAL_OK)
  {
    Error_Handler();
  }

  /** Configure Regular Channel
  */
  sConfig.Channel = ADC_CHANNEL_7;
  sConfig.Rank = ADC_REGULAR_RANK_1;
  sConfig.SamplingTime = ADC_SAMPLETIME_640CYCLES_5;
  sConfig.SingleDiff = ADC_SINGLE_ENDED;
  sConfig.OffsetNumber = ADC_OFFSET_NONE;
  sConfig.Offset = 0;
  if (HAL_ADC_ConfigChannel(&hadc2, &sConfig) != HAL_OK)
  {
    Error_Handler();
  }

  /** Configure Regular Channel
  */
  sConfig.Channel = ADC_CHANNEL_8;
  sConfig.Rank = ADC_REGULAR_RANK_2;
  if (HAL_ADC_ConfigChannel(&hadc2, &sConfig) != HAL_OK)
  {
    Error_Handler();
  }

  /** Configure Regular Channel
  */
  sConfig.Channel = ADC_CHANNEL_9;
  sConfig.Rank = ADC_REGULAR_RANK_3;
  if (HAL_ADC_ConfigChannel(&hadc2, &sConfig) != HAL_OK)
  {
    Error_Handler();
  }

  /** Configure Regular Channel
  */
  sConfig.Channel = ADC_CHANNEL_17;
  sConfig.Rank = ADC_REGULAR_RANK_4;
  if (HAL_ADC_ConfigChannel(&hadc2, &sConfig) != HAL_OK)
  {
    Error_Handler();
  }

  /** Configure Regular Channel
  */
  sConfig.Channel = ADC_CHANNEL_13;
  sConfig.Rank = ADC_REGULAR_RANK_5;
  if (HAL_ADC_ConfigChannel(&hadc2, &sConfig) != HAL_OK)
  {
    Error_Handler();
  }

  /** Configure Regular Channel
  */
  sConfig.Channel = ADC_CHANNEL_3;
  sConfig.Rank = ADC_REGULAR_RANK_6;
  if (HAL_ADC_ConfigChannel(&hadc2, &sConfig) != HAL_OK)
  {
    Error_Handler();
  }

  /** Configure Regular Channel
  */
  sConfig.Channel = ADC_CHANNEL_4;
  sConfig.Rank = ADC_REGULAR_RANK_7;
  if (HAL_ADC_ConfigChannel(&hadc2, &sConfig) != HAL_OK)
  {
    Error_Handler();
  }

  /** Configure Regular Channel
  */
  sConfig.Channel = ADC_CHANNEL_5;
  sConfig.Rank = ADC_REGULAR_RANK_8;
  if (HAL_ADC_ConfigChannel(&hadc2, &sConfig) != HAL_OK)
  {
    Error_Handler();
  }

  /** Configure Regular Channel
  */
  sConfig.Channel = ADC_CHANNEL_11;
  sConfig.Rank = ADC_REGULAR_RANK_9;
  if (HAL_ADC_ConfigChannel(&hadc2, &sConfig) != HAL_OK)
  {
    Error_Handler();
  }

}

static void MX_ADC4_Init(void)
{

  ADC_ChannelConfTypeDef sConfig = {0};

  /** Common config
  */
  hadc4.Instance = ADC4;
  hadc4.Init.ClockPrescaler = ADC_CLOCK_SYNC_PCLK_DIV4;
  hadc4.Init.Resolution = ADC_RESOLUTION_12B;
  hadc4.Init.DataAlign = ADC_DATAALIGN_RIGHT;
  hadc4.Init.GainCompensation = 0;
  hadc4.Init.ScanConvMode = ADC_SCAN_ENABLE;
  hadc4.Init.EOCSelection = ADC_EOC_SINGLE_CONV;
  hadc4.Init.LowPowerAutoWait = DISABLE;
  hadc4.Init.ContinuousConvMode = ENABLE;
  hadc4.Init.NbrOfConversion = 2;
  hadc4.Init.DiscontinuousConvMode = DISABLE;
  hadc4.Init.ExternalTrigConv = ADC_SOFTWARE_START;
  hadc4.Init.ExternalTrigConvEdge = ADC_EXTERNALTRIGCONVEDGE_NONE;
  hadc4.Init.DMAContinuousRequests = ENABLE;
  hadc4.Init.Overrun = ADC_OVR_DATA_PRESERVED;
  hadc4.Init.OversamplingMode = DISABLE;
  if (HAL_ADC_Init(&hadc4) != HAL_OK)
  {
    Error_Handler();
  }

  /** Configure Regular Channel
  */
  sConfig.Channel = ADC_CHANNEL_3;
  sConfig.Rank = ADC_REGULAR_RANK_1;
  sConfig.SamplingTime = ADC_SAMPLETIME_640CYCLES_5;
  sConfig.SingleDiff = ADC_SINGLE_ENDED;
  sConfig.OffsetNumber = ADC_OFFSET_NONE;
  sConfig.Offset = 0;
  if (HAL_ADC_ConfigChannel(&hadc4, &sConfig) != HAL_OK)
  {
    Error_Handler();
  }

  /** Configure Regular Channel
  */
  sConfig.Channel = ADC_CHANNEL_4;
  sConfig.Rank = ADC_REGULAR_RANK_2;
  if (HAL_ADC_ConfigChannel(&hadc4, &sConfig) != HAL_OK)
  {
    Error_Handler();
  }

}

static void MX_FDCAN1_Init(void)
{

  hfdcan1.Instance = FDCAN1;
  hfdcan1.Init.ClockDivider = FDCAN_CLOCK_DIV1;
  hfdcan1.Init.FrameFormat = FDCAN_FRAME_CLASSIC;
  hfdcan1.Init.Mode = FDCAN_MODE_NORMAL;
  hfdcan1.Init.AutoRetransmission = DISABLE;
  hfdcan1.Init.TransmitPause = DISABLE;
  hfdcan1.Init.ProtocolException = DISABLE;
  hfdcan1.Init.NominalPrescaler = 32;
  hfdcan1.Init.NominalSyncJumpWidth = 1;
  hfdcan1.Init.NominalTimeSeg1 = 4;
  hfdcan1.Init.NominalTimeSeg2 = 5;
  hfdcan1.Init.DataPrescaler = 32;
  hfdcan1.Init.DataSyncJumpWidth = 1;
  hfdcan1.Init.DataTimeSeg1 = 4;
  hfdcan1.Init.DataTimeSeg2 = 5;
  hfdcan1.Init.StdFiltersNbr = 0;
  hfdcan1.Init.ExtFiltersNbr = 0;
  hfdcan1.Init.TxFifoQueueMode = FDCAN_TX_FIFO_OPERATION;
  if (HAL_FDCAN_Init(&hfdcan1) != HAL_OK)
  {
    Error_Handler();
  }

}

static void MX_FDCAN2_Init(void)
{

  hfdcan2.Instance = FDCAN2;
  hfdcan2.Init.ClockDivider = FDCAN_CLOCK_DIV1;
  hfdcan2.Init.FrameFormat = FDCAN_FRAME_CLASSIC;
  hfdcan2.Init.Mode = FDCAN_MODE_NORMAL;
  hfdcan2.Init.AutoRetransmission = DISABLE;
  hfdcan2.Init.TransmitPause = DISABLE;
  hfdcan2.Init.ProtocolException = DISABLE;
  hfdcan2.Init.NominalPrescaler = 32;
  hfdcan2.Init.NominalSyncJumpWidth = 1;
  hfdcan2.Init.NominalTimeSeg1 = 4;
  hfdcan2.Init.NominalTimeSeg2 = 5;
  hfdcan2.Init.DataPrescaler = 32;
  hfdcan2.Init.DataSyncJumpWidth = 1;
  hfdcan2.Init.DataTimeSeg1 = 4;
  hfdcan2.Init.DataTimeSeg2 = 5;
  hfdcan2.Init.StdFiltersNbr = 12;
  hfdcan2.Init.ExtFiltersNbr = 1;
  hfdcan2.Init.TxFifoQueueMode = FDCAN_TX_FIFO_OPERATION;
  if (HAL_FDCAN_Init(&hfdcan2) != HAL_OK)
  {
    Error_Handler();
  }

}

static void MX_I2C3_Init(void)
{

  hi2c3.Instance = I2C3;
  hi2c3.Init.Timing = 0x30D29DE4;
  hi2c3.Init.OwnAddress1 = 0;
  hi2c3.Init.AddressingMode = I2C_ADDRESSINGMODE_7BIT;
  hi2c3.Init.DualAddressMode = I2C_DUALADDRESS_DISABLE;
  hi2c3.Init.OwnAddress2 = 0;
  hi2c3.Init.OwnAddress2Masks = I2C_OA2_NOMASK;
  hi2c3.Init.GeneralCallMode = I2C_GENERALCALL_DISABLE;
  hi2c3.Init.NoStretchMode = I2C_NOSTRETCH_DISABLE;
  if (HAL_I2C_Init(&hi2c3) != HAL_OK)
  {
    Error_Handler();
  }

  /** Configure Analogue filter
  */
  if (HAL_I2CEx_ConfigAnalogFilter(&hi2c3, I2C_ANALOGFILTER_ENABLE) != HAL_OK)
  {
    Error_Handler();
  }

  /** Configure Digital filter
  */
  if (HAL_I2CEx_ConfigDigitalFilter(&hi2c3, 0) != HAL_OK)
  {
    Error_Handler();
  }

}

static void MX_TIM1_Init(void)
{

  TIM_ClockConfigTypeDef sClockSourceConfig = {0};
  TIM_MasterConfigTypeDef sMasterConfig = {0};
  TIM_OC_InitTypeDef sConfigOC = {0};
  TIM_BreakDeadTimeConfigTypeDef sBreakDeadTimeConfig = {0};

  htim1.Instance = TIM1;
  htim1.Init.Prescaler = 0;
  htim1.Init.CounterMode = TIM_COUNTERMODE_UP;
  htim1.Init.Period = 1599;
  htim1.Init.ClockDivision = TIM_CLOCKDIVISION_DIV1;
  htim1.Init.RepetitionCounter = 0;
  htim1.Init.AutoReloadPreload = TIM_AUTORELOAD_PRELOAD_DISABLE;
  if (HAL_TIM_Base_Init(&htim1) != HAL_OK)
  {
    Error_Handler();
  }
  sClockSourceConfig.ClockSource = TIM_CLOCKSOURCE_INTERNAL;
  if (HAL_TIM_ConfigClockSource(&htim1, &sClockSourceConfig) != HAL_OK)
  {
    Error_Handler();
  }
  if (HAL_TIM_PWM_Init(&htim1) != HAL_OK)
  {
    Error_Handler();
  }
  sMasterConfig.MasterOutputTrigger = TIM_TRGO_RESET;
  sMasterConfig.MasterOutputTrigger2 = TIM_TRGO2_RESET;
  sMasterConfig.MasterSlaveMode = TIM_MASTERSLAVEMODE_DISABLE;
  if (HAL_TIMEx_MasterConfigSynchronization(&htim1, &sMasterConfig) != HAL_OK)
  {
    Error_Handler();
  }
  sConfigOC.OCMode = TIM_OCMODE_PWM1;
  sConfigOC.Pulse = 0;
  sConfigOC.OCPolarity = TIM_OCPOLARITY_HIGH;
  sConfigOC.OCNPolarity = TIM_OCNPOLARITY_HIGH;
  sConfigOC.OCFastMode = TIM_OCFAST_DISABLE;
  sConfigOC.OCIdleState = TIM_OCIDLESTATE_RESET;
  sConfigOC.OCNIdleState = TIM_OCNIDLESTATE_RESET;
  if (HAL_TIM_PWM_ConfigChannel(&htim1, &sConfigOC, TIM_CHANNEL_1) != HAL_OK)
  {
    Error_Handler();
  }
  sBreakDeadTimeConfig.OffStateRunMode = TIM_OSSR_DISABLE;
  sBreakDeadTimeConfig.OffStateIDLEMode = TIM_OSSI_DISABLE;
  sBreakDeadTimeConfig.LockLevel = TIM_LOCKLEVEL_OFF;
  sBreakDeadTimeConfig.DeadTime = 0;
  sBreakDeadTimeConfig.BreakState = TIM_BREAK_DISABLE;
  sBreakDeadTimeConfig.BreakPolarity = TIM_BREAKPOLARITY_HIGH;
  sBreakDeadTimeConfig.BreakFilter = 0;
  sBreakDeadTimeConfig.BreakAFMode = TIM_BREAK_AFMODE_INPUT;
  sBreakDeadTimeConfig.Break2State = TIM_BREAK2_DISABLE;
  sBreakDeadTimeConfig.Break2Polarity = TIM_BREAK2POLARITY_HIGH;
  sBreakDeadTimeConfig.Break2Filter = 0;
  sBreakDeadTimeConfig.Break2AFMode = TIM_BREAK_AFMODE_INPUT;
  sBreakDeadTimeConfig.AutomaticOutput = TIM_AUTOMATICOUTPUT_DISABLE;
  if (HAL_TIMEx_ConfigBreakDeadTime(&htim1, &sBreakDeadTimeConfig) != HAL_OK)
  {
    Error_Handler();
  }
  HAL_TIM_MspPostInit(&htim1);

}

static void MX_TIM2_Init(void)
{

  TIM_ClockConfigTypeDef sClockSourceConfig = {0};
  TIM_MasterConfigTypeDef sMasterConfig = {0};

  htim2.Instance = TIM2;
  htim2.Init.Prescaler = 1599;
  htim2.Init.CounterMode = TIM_COUNTERMODE_UP;
  htim2.Init.Period = 999;
  htim2.Init.ClockDivision = TIM_CLOCKDIVISION_DIV1;
  htim2.Init.AutoReloadPreload = TIM_AUTORELOAD_PRELOAD_DISABLE;
  if (HAL_TIM_Base_Init(&htim2) != HAL_OK)
  {
    Error_Handler();
  }
  sClockSourceConfig.ClockSource = TIM_CLOCKSOURCE_INTERNAL;
  if (HAL_TIM_ConfigClockSource(&htim2, &sClockSourceConfig) != HAL_OK)
  {
    Error_Handler();
  }
  sMasterConfig.MasterOutputTrigger = TIM_TRGO_RESET;
  sMasterConfig.MasterSlaveMode = TIM_MASTERSLAVEMODE_DISABLE;
  if (HAL_TIMEx_MasterConfigSynchronization(&htim2, &sMasterConfig) != HAL_OK)
  {
    Error_Handler();
  }

}

static void MX_TIM3_Init(void)
{

  TIM_ClockConfigTypeDef sClockSourceConfig = {0};
  TIM_MasterConfigTypeDef sMasterConfig = {0};

  htim3.Instance = TIM3;
  htim3.Init.Prescaler = 0;
  htim3.Init.CounterMode = TIM_COUNTERMODE_UP;
  htim3.Init.Period = 1599;
  htim3.Init.ClockDivision = TIM_CLOCKDIVISION_DIV1;
  htim3.Init.AutoReloadPreload = TIM_AUTORELOAD_PRELOAD_DISABLE;
  if (HAL_TIM_Base_Init(&htim3) != HAL_OK)
  {
    Error_Handler();
  }
  sClockSourceConfig.ClockSource = TIM_CLOCKSOURCE_INTERNAL;
  if (HAL_TIM_ConfigClockSource(&htim3, &sClockSourceConfig) != HAL_OK)
  {
    Error_Handler();
  }
  sMasterConfig.MasterOutputTrigger = TIM_TRGO_RESET;
  sMasterConfig.MasterSlaveMode = TIM_MASTERSLAVEMODE_DISABLE;
  if (HAL_TIMEx_MasterConfigSynchronization(&htim3, &sMasterConfig) != HAL_OK)
  {
    Error_Handler();
  }

}

static void MX_TIM8_Init(void)
{

  TIM_ClockConfigTypeDef sClockSourceConfig = {0};
  TIM_MasterConfigTypeDef sMasterConfig = {0};
  TIM_OC_InitTypeDef sConfigOC = {0};
  TIM_BreakDeadTimeConfigTypeDef sBreakDeadTimeConfig = {0};

  htim8.Instance = TIM8;
  htim8.Init.Prescaler = 0;
  htim8.Init.CounterMode = TIM_COUNTERMODE_UP;
  htim8.Init.Period = 1599;
  htim8.Init.ClockDivision = TIM_CLOCKDIVISION_DIV1;
  htim8.Init.RepetitionCounter = 0;
  htim8.Init.AutoReloadPreload = TIM_AUTORELOAD_PRELOAD_DISABLE;
  if (HAL_TIM_Base_Init(&htim8) != HAL_OK)
  {
    Error_Handler();
  }
  sClockSourceConfig.ClockSource = TIM_CLOCKSOURCE_INTERNAL;
  if (HAL_TIM_ConfigClockSource(&htim8, &sClockSourceConfig) != HAL_OK)
  {
    Error_Handler();
  }
  if (HAL_TIM_PWM_Init(&htim8) != HAL_OK)
  {
    Error_Handler();
  }
  sMasterConfig.MasterOutputTrigger = TIM_TRGO_RESET;
  sMasterConfig.MasterOutputTrigger2 = TIM_TRGO2_RESET;
  sMasterConfig.MasterSlaveMode = TIM_MASTERSLAVEMODE_DISABLE;
  if (HAL_TIMEx_MasterConfigSynchronization(&htim8, &sMasterConfig) != HAL_OK)
  {
    Error_Handler();
  }
  sConfigOC.OCMode = TIM_OCMODE_PWM1;
  sConfigOC.Pulse = 0;
  sConfigOC.OCPolarity = TIM_OCPOLARITY_HIGH;
  sConfigOC.OCNPolarity = TIM_OCNPOLARITY_HIGH;
  sConfigOC.OCFastMode = TIM_OCFAST_DISABLE;
  sConfigOC.OCIdleState = TIM_OCIDLESTATE_RESET;
  sConfigOC.OCNIdleState = TIM_OCNIDLESTATE_RESET;
  if (HAL_TIM_PWM_ConfigChannel(&htim8, &sConfigOC, TIM_CHANNEL_1) != HAL_OK)
  {
    Error_Handler();
  }
  sBreakDeadTimeConfig.OffStateRunMode = TIM_OSSR_DISABLE;
  sBreakDeadTimeConfig.OffStateIDLEMode = TIM_OSSI_DISABLE;
  sBreakDeadTimeConfig.LockLevel = TIM_LOCKLEVEL_OFF;
  sBreakDeadTimeConfig.DeadTime = 0;
  sBreakDeadTimeConfig.BreakState = TIM_BREAK_DISABLE;
  sBreakDeadTimeConfig.BreakPolarity = TIM_BREAKPOLARITY_HIGH;
  sBreakDeadTimeConfig.BreakFilter = 0;
  sBreakDeadTimeConfig.BreakAFMode = TIM_BREAK_AFMODE_INPUT;
  sBreakDeadTimeConfig.Break2State = TIM_BREAK2_DISABLE;
  sBreakDeadTimeConfig.Break2Polarity = TIM_BREAK2POLARITY_HIGH;
  sBreakDeadTimeConfig.Break2Filter = 0;
  sBreakDeadTimeConfig.Break2AFMode = TIM_BREAK_AFMODE_INPUT;
  sBreakDeadTimeConfig.AutomaticOutput = TIM_AUTOMATICOUTPUT_DISABLE;
  if (HAL_TIMEx_ConfigBreakDeadTime(&htim8, &sBreakDeadTimeConfig) != HAL_OK)
  {
    Error_Handler();
  }
  HAL_TIM_MspPostInit(&htim8);

}

static void MX_TIM15_Init(void)
{

  TIM_ClockConfigTypeDef sClockSourceConfig = {0};
  TIM_MasterConfigTypeDef sMasterConfig = {0};
  TIM_OC_InitTypeDef sConfigOC = {0};
  TIM_BreakDeadTimeConfigTypeDef sBreakDeadTimeConfig = {0};

  htim15.Instance = TIM15;
  htim15.Init.Prescaler = 0;
  htim15.Init.CounterMode = TIM_COUNTERMODE_UP;
  htim15.Init.Period = 1599;
  htim15.Init.ClockDivision = TIM_CLOCKDIVISION_DIV1;
  htim15.Init.RepetitionCounter = 0;
  htim15.Init.AutoReloadPreload = TIM_AUTORELOAD_PRELOAD_DISABLE;
  if (HAL_TIM_Base_Init(&htim15) != HAL_OK)
  {
    Error_Handler();
  }
  sClockSourceConfig.ClockSource = TIM_CLOCKSOURCE_INTERNAL;
  if (HAL_TIM_ConfigClockSource(&htim15, &sClockSourceConfig) != HAL_OK)
  {
    Error_Handler();
  }
  if (HAL_TIM_PWM_Init(&htim15) != HAL_OK)
  {
    Error_Handler();
  }
  sMasterConfig.MasterOutputTrigger = TIM_TRGO_RESET;
  sMasterConfig.MasterSlaveMode = TIM_MASTERSLAVEMODE_DISABLE;
  if (HAL_TIMEx_MasterConfigSynchronization(&htim15, &sMasterConfig) != HAL_OK)
  {
    Error_Handler();
  }
  sConfigOC.OCMode = TIM_OCMODE_PWM1;
  sConfigOC.Pulse = 0;
  sConfigOC.OCPolarity = TIM_OCPOLARITY_HIGH;
  sConfigOC.OCNPolarity = TIM_OCNPOLARITY_HIGH;
  sConfigOC.OCFastMode = TIM_OCFAST_DISABLE;
  sConfigOC.OCIdleState = TIM_OCIDLESTATE_RESET;
  sConfigOC.OCNIdleState = TIM_OCNIDLESTATE_RESET;
  if (HAL_TIM_PWM_ConfigChannel(&htim15, &sConfigOC, TIM_CHANNEL_1) != HAL_OK)
  {
    Error_Handler();
  }
  sBreakDeadTimeConfig.OffStateRunMode = TIM_OSSR_DISABLE;
  sBreakDeadTimeConfig.OffStateIDLEMode = TIM_OSSI_DISABLE;
  sBreakDeadTimeConfig.LockLevel = TIM_LOCKLEVEL_OFF;
  sBreakDeadTimeConfig.DeadTime = 0;
  sBreakDeadTimeConfig.BreakState = TIM_BREAK_DISABLE;
  sBreakDeadTimeConfig.BreakPolarity = TIM_BREAKPOLARITY_HIGH;
  sBreakDeadTimeConfig.BreakFilter = 0;
  sBreakDeadTimeConfig.AutomaticOutput = TIM_AUTOMATICOUTPUT_DISABLE;
  if (HAL_TIMEx_ConfigBreakDeadTime(&htim15, &sBreakDeadTimeConfig) != HAL_OK)
  {
    Error_Handler();
  }
  HAL_TIM_MspPostInit(&htim15);

}

static void MX_TIM17_Init(void)
{

  TIM_OC_InitTypeDef sConfigOC = {0};
  TIM_BreakDeadTimeConfigTypeDef sBreakDeadTimeConfig = {0};

  htim17.Instance = TIM17;
  htim17.Init.Prescaler = 0;
  htim17.Init.CounterMode = TIM_COUNTERMODE_UP;
  htim17.Init.Period = 1599;
  htim17.Init.ClockDivision = TIM_CLOCKDIVISION_DIV1;
  htim17.Init.RepetitionCounter = 0;
  htim17.Init.AutoReloadPreload = TIM_AUTORELOAD_PRELOAD_DISABLE;
  if (HAL_TIM_Base_Init(&htim17) != HAL_OK)
  {
    Error_Handler();
  }
  if (HAL_TIM_PWM_Init(&htim17) != HAL_OK)
  {
    Error_Handler();
  }
  sConfigOC.OCMode = TIM_OCMODE_PWM1;
  sConfigOC.Pulse = 0;
  sConfigOC.OCPolarity = TIM_OCPOLARITY_HIGH;
  sConfigOC.OCNPolarity = TIM_OCNPOLARITY_HIGH;
  sConfigOC.OCFastMode = TIM_OCFAST_DISABLE;
  sConfigOC.OCIdleState = TIM_OCIDLESTATE_RESET;
  sConfigOC.OCNIdleState = TIM_OCNIDLESTATE_RESET;
  if (HAL_TIM_PWM_ConfigChannel(&htim17, &sConfigOC, TIM_CHANNEL_1) != HAL_OK)
  {
    Error_Handler();
  }
  sBreakDeadTimeConfig.OffStateRunMode = TIM_OSSR_DISABLE;
  sBreakDeadTimeConfig.OffStateIDLEMode = TIM_OSSI_DISABLE;
  sBreakDeadTimeConfig.LockLevel = TIM_LOCKLEVEL_OFF;
  sBreakDeadTimeConfig.DeadTime = 0;
  sBreakDeadTimeConfig.BreakState = TIM_BREAK_DISABLE;
  sBreakDeadTimeConfig.BreakPolarity = TIM_BREAKPOLARITY_HIGH;
  sBreakDeadTimeConfig.BreakFilter = 0;
  sBreakDeadTimeConfig.AutomaticOutput = TIM_AUTOMATICOUTPUT_DISABLE;
  if (HAL_TIMEx_ConfigBreakDeadTime(&htim17, &sBreakDeadTimeConfig) != HAL_OK)
  {
    Error_Handler();
  }
  HAL_TIM_MspPostInit(&htim17);

}

static void MX_UART5_Init(void)
{

  huart5.Instance = UART5;
  huart5.Init.BaudRate = 115200;
  huart5.Init.WordLength = UART_WORDLENGTH_8B;
  huart5.Init.StopBits = UART_STOPBITS_1;
  huart5.Init.Parity = UART_PARITY_NONE;
  huart5.Init.Mode = UART_MODE_TX_RX;
  huart5.Init.HwFlowCtl = UART_HWCONTROL_NONE;
  huart5.Init.OverSampling = UART_OVERSAMPLING_16;
  huart5.Init.OneBitSampling = UART_ONE_BIT_SAMPLE_DISABLE;
  huart5.Init.ClockPrescaler = UART_PRESCALER_DIV1;
  huart5.AdvancedInit.AdvFeatureInit = UART_ADVFEATURE_NO_INIT;
  if (HAL_UART_Init(&huart5) != HAL_OK)
  {
    Error_Handler();
  }
  if (HAL_UARTEx_SetTxFifoThreshold(&huart5, UART_TXFIFO_THRESHOLD_1_8) != HAL_OK)
  {
    Error_Handler();
  }
  if (HAL_UARTEx_SetRxFifoThreshold(&huart5, UART_RXFIFO_THRESHOLD_1_8) != HAL_OK)
  {
    Error_Handler();
  }
  if (HAL_UARTEx_DisableFifoMode(&huart5) != HAL_OK)
  {
    Error_Handler();
  }

}

static void MX_USART3_UART_Init(void)
{

  huart3.Instance = USART3;
  huart3.Init.BaudRate = 115200;
  huart3.Init.WordLength = UART_WORDLENGTH_8B;
  huart3.Init.StopBits = UART_STOPBITS_1;
  huart3.Init.Parity = UART_PARITY_NONE;
  huart3.Init.Mode = UART_MODE_TX_RX;
  huart3.Init.HwFlowCtl = UART_HWCONTROL_NONE;
  huart3.Init.OverSampling = UART_OVERSAMPLING_16;
  huart3.Init.OneBitSampling = UART_ONE_BIT_SAMPLE_DISABLE;
  huart3.Init.ClockPrescaler = UART_PRESCALER_DIV1;
  huart3.AdvancedInit.AdvFeatureInit = UART_ADVFEATURE_NO_INIT;
  if (HAL_UART_Init(&huart3) != HAL_OK)
  {
    Error_Handler();
  }
  if (HAL_UARTEx_SetTxFifoThreshold(&huart3, UART_TXFIFO_THRESHOLD_1_8) != HAL_OK)
  {
    Error_Handler();
  }
  if (HAL_UARTEx_SetRxFifoThreshold(&huart3, UART_RXFIFO_THRESHOLD_1_8) != HAL_OK)
  {
    Error_Handler();
  }
  if (HAL_UARTEx_DisableFifoMode(&huart3) != HAL_OK)
  {
    Error_Handler();
  }

}

static void MX_DMA_Init(void)
{

  /* DMA controller clock enable */
  __HAL_RCC_DMAMUX1_CLK_ENABLE();
  __HAL_RCC_DMA1_CLK_ENABLE();

  /* DMA interrupt init */
  /* DMA1_Channel1_IRQn interrupt configuration */
  HAL_NVIC_SetPriority(DMA1_Channel1_IRQn, 0, 0);
  HAL_NVIC_EnableIRQ(DMA1_Channel1_IRQn);
  /* DMA1_Channel2_IRQn interrupt configuration */
  HAL_NVIC_SetPriority(DMA1_Channel2_IRQn, 0, 0);
  HAL_NVIC_EnableIRQ(DMA1_Channel2_IRQn);
  /* DMA1_Channel3_IRQn interrupt configuration */
  HAL_NVIC_SetPriority(DMA1_Channel3_IRQn, 0, 0);
  HAL_NVIC_EnableIRQ(DMA1_Channel3_IRQn);

}

static void MX_GPIO_Init(void)
{
  GPIO_InitTypeDef GPIO_InitStruct = {0};

  /* GPIO Ports Clock Enable */
  __HAL_RCC_GPIOC_CLK_ENABLE();
  __HAL_RCC_GPIOA_CLK_ENABLE();
  __HAL_RCC_GPIOB_CLK_ENABLE();
  __HAL_RCC_GPIOD_CLK_ENABLE();

  /*Configure GPIO pin Output Level */
  HAL_GPIO_WritePin(GPIOC, GPIO_PIN_7|GPIO_PIN_11, GPIO_PIN_RESET);

  /*Configure GPIO pin Output Level */
  HAL_GPIO_WritePin(GPIOA, GPIO_PIN_8|GPIO_PIN_9|GPIO_PIN_10, GPIO_PIN_RESET);

  /*Configure GPIO pin : PA0 */
  GPIO_InitStruct.Pin = GPIO_PIN_0;
  GPIO_InitStruct.Mode = GPIO_MODE_INPUT;
  GPIO_InitStruct.Pull = GPIO_NOPULL;
  HAL_GPIO_Init(GPIOA, &GPIO_InitStruct);

  /*Configure GPIO pin : PA3 */
  GPIO_InitStruct.Pin = GPIO_PIN_3;
  GPIO_InitStruct.Mode = GPIO_MODE_INPUT;
  GPIO_InitStruct.Pull = GPIO_PULLDOWN;
  HAL_GPIO_Init(GPIOA, &GPIO_InitStruct);

  /*Configure GPIO pin : PB2 */
  GPIO_InitStruct.Pin = GPIO_PIN_2;
  GPIO_InitStruct.Mode = GPIO_MODE_INPUT;
  GPIO_InitStruct.Pull = GPIO_NOPULL;
  HAL_GPIO_Init(GPIOB, &GPIO_InitStruct);

  /*Configure GPIO pins : PC7 PC11 */
  GPIO_InitStruct.Pin = GPIO_PIN_7|GPIO_PIN_11;
  GPIO_InitStruct.Mode = GPIO_MODE_OUTPUT_PP;
  GPIO_InitStruct.Pull = GPIO_NOPULL;
  GPIO_InitStruct.Speed = GPIO_SPEED_FREQ_LOW;
  HAL_GPIO_Init(GPIOC, &GPIO_InitStruct);

  /*Configure GPIO pins : PA8 PA9 PA10 */
  GPIO_InitStruct.Pin = GPIO_PIN_8|GPIO_PIN_9|GPIO_PIN_10;
  GPIO_InitStruct.Mode = GPIO_MODE_OUTPUT_PP;
  GPIO_InitStruct.Pull = GPIO_NOPULL;
  GPIO_InitStruct.Speed = GPIO_SPEED_FREQ_LOW;
  HAL_GPIO_Init(GPIOA, &GPIO_InitStruct);

}

void Error_Handler(void)
{
  __disable_irq();
  while (1)
  {
  }
}
